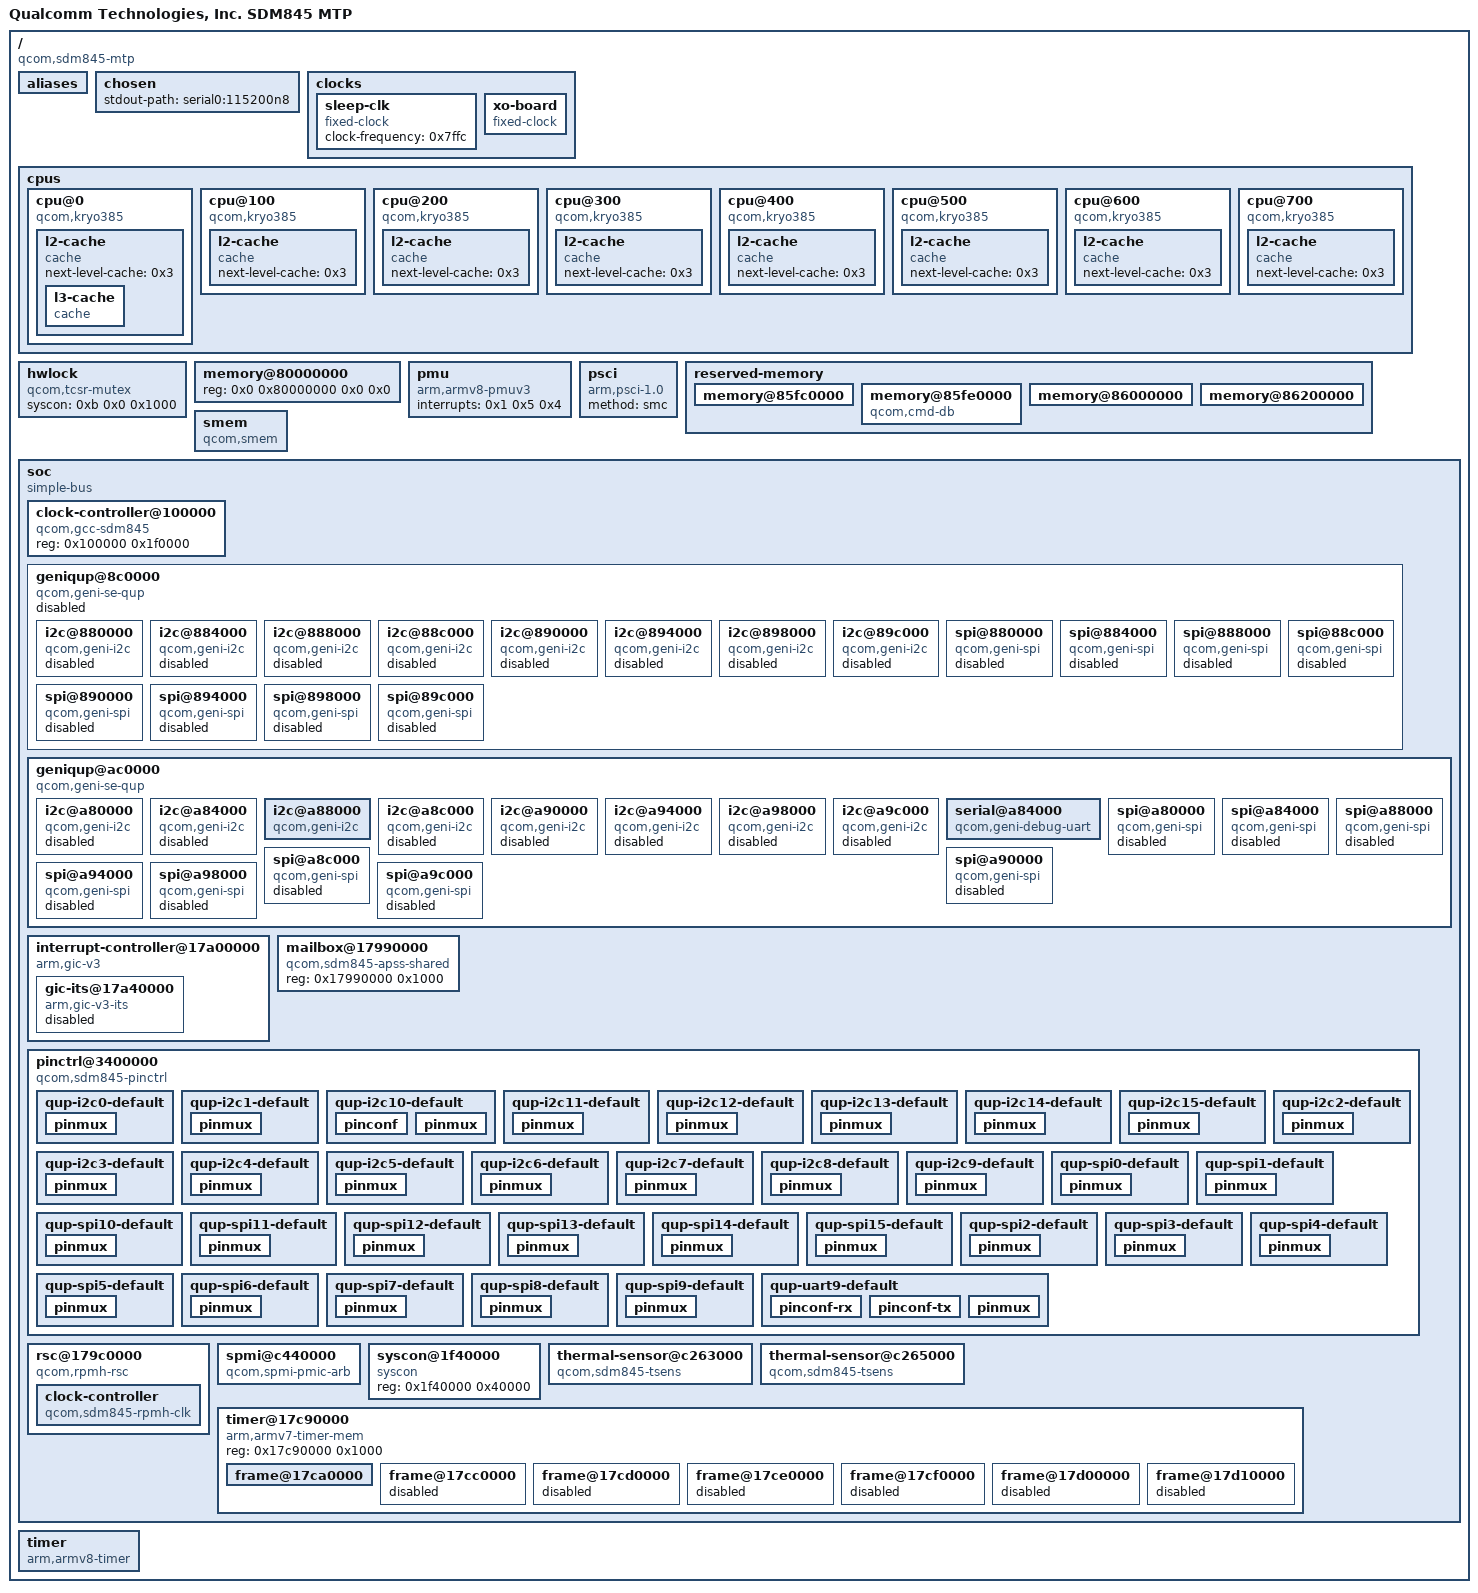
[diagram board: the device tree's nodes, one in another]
/dts-v1/;

/ {
	#address-cells = <0x2>;
	#size-cells = <0x2>;
	compatible = "qcom,sdm845-mtp";
	interrupt-parent = <0x1>;
	model = "Qualcomm Technologies, Inc. SDM845 MTP";

	__symbols__ {
		CPU0 = "/cpus/cpu@0";
		CPU1 = "/cpus/cpu@100";
		CPU2 = "/cpus/cpu@200";
		CPU3 = "/cpus/cpu@300";
		CPU4 = "/cpus/cpu@400";
		CPU5 = "/cpus/cpu@500";
		CPU6 = "/cpus/cpu@600";
		CPU7 = "/cpus/cpu@700";
		L2_0 = "/cpus/cpu@0/l2-cache";
		L2_100 = "/cpus/cpu@100/l2-cache";
		L2_200 = "/cpus/cpu@200/l2-cache";
		L2_300 = "/cpus/cpu@300/l2-cache";
		L2_400 = "/cpus/cpu@400/l2-cache";
		L2_500 = "/cpus/cpu@500/l2-cache";
		L2_600 = "/cpus/cpu@600/l2-cache";
		L2_700 = "/cpus/cpu@700/l2-cache";
		L3_0 = "/cpus/cpu@0/l2-cache/l3-cache";
		apps_rsc = "/soc/rsc@179c0000";
		apss_shared = "/soc/mailbox@17990000";
		gcc = "/soc/clock-controller@100000";
		i2c0 = "/soc/geniqup@8c0000/i2c@880000";
		i2c1 = "/soc/geniqup@8c0000/i2c@884000";
		i2c10 = "/soc/geniqup@ac0000/i2c@a88000";
		i2c11 = "/soc/geniqup@ac0000/i2c@a8c000";
		i2c12 = "/soc/geniqup@ac0000/i2c@a90000";
		i2c13 = "/soc/geniqup@ac0000/i2c@a94000";
		i2c14 = "/soc/geniqup@ac0000/i2c@a98000";
		i2c15 = "/soc/geniqup@ac0000/i2c@a9c000";
		i2c2 = "/soc/geniqup@8c0000/i2c@888000";
		i2c3 = "/soc/geniqup@8c0000/i2c@88c000";
		i2c4 = "/soc/geniqup@8c0000/i2c@890000";
		i2c5 = "/soc/geniqup@8c0000/i2c@894000";
		i2c6 = "/soc/geniqup@8c0000/i2c@898000";
		i2c7 = "/soc/geniqup@8c0000/i2c@89c000";
		i2c8 = "/soc/geniqup@ac0000/i2c@a80000";
		i2c9 = "/soc/geniqup@ac0000/i2c@a84000";
		intc = "/soc/interrupt-controller@17a00000";
		qup_i2c0_default = "/soc/pinctrl@3400000/qup-i2c0-default";
		qup_i2c10_default = "/soc/pinctrl@3400000/qup-i2c10-default";
		qup_i2c11_default = "/soc/pinctrl@3400000/qup-i2c11-default";
		qup_i2c12_default = "/soc/pinctrl@3400000/qup-i2c12-default";
		qup_i2c13_default = "/soc/pinctrl@3400000/qup-i2c13-default";
		qup_i2c14_default = "/soc/pinctrl@3400000/qup-i2c14-default";
		qup_i2c15_default = "/soc/pinctrl@3400000/qup-i2c15-default";
		qup_i2c1_default = "/soc/pinctrl@3400000/qup-i2c1-default";
		qup_i2c2_default = "/soc/pinctrl@3400000/qup-i2c2-default";
		qup_i2c3_default = "/soc/pinctrl@3400000/qup-i2c3-default";
		qup_i2c4_default = "/soc/pinctrl@3400000/qup-i2c4-default";
		qup_i2c5_default = "/soc/pinctrl@3400000/qup-i2c5-default";
		qup_i2c6_default = "/soc/pinctrl@3400000/qup-i2c6-default";
		qup_i2c7_default = "/soc/pinctrl@3400000/qup-i2c7-default";
		qup_i2c8_default = "/soc/pinctrl@3400000/qup-i2c8-default";
		qup_i2c9_default = "/soc/pinctrl@3400000/qup-i2c9-default";
		qup_spi0_default = "/soc/pinctrl@3400000/qup-spi0-default";
		qup_spi10_default = "/soc/pinctrl@3400000/qup-spi10-default";
		qup_spi11_default = "/soc/pinctrl@3400000/qup-spi11-default";
		qup_spi12_default = "/soc/pinctrl@3400000/qup-spi12-default";
		qup_spi13_default = "/soc/pinctrl@3400000/qup-spi13-default";
		qup_spi14_default = "/soc/pinctrl@3400000/qup-spi14-default";
		qup_spi15_default = "/soc/pinctrl@3400000/qup-spi15-default";
		qup_spi1_default = "/soc/pinctrl@3400000/qup-spi1-default";
		qup_spi2_default = "/soc/pinctrl@3400000/qup-spi2-default";
		qup_spi3_default = "/soc/pinctrl@3400000/qup-spi3-default";
		qup_spi4_default = "/soc/pinctrl@3400000/qup-spi4-default";
		qup_spi5_default = "/soc/pinctrl@3400000/qup-spi5-default";
		qup_spi6_default = "/soc/pinctrl@3400000/qup-spi6-default";
		qup_spi7_default = "/soc/pinctrl@3400000/qup-spi7-default";
		qup_spi8_default = "/soc/pinctrl@3400000/qup-spi8-default";
		qup_spi9_default = "/soc/pinctrl@3400000/qup-spi9-default";
		qup_uart9_default = "/soc/pinctrl@3400000/qup-uart9-default";
		qupv3_id_0 = "/soc/geniqup@8c0000";
		qupv3_id_1 = "/soc/geniqup@ac0000";
		rpmhcc = "/soc/rsc@179c0000/clock-controller";
		sleep_clk = "/clocks/sleep-clk";
		smem_mem = "/reserved-memory/memory@86000000";
		soc = "/soc";
		spi0 = "/soc/geniqup@8c0000/spi@880000";
		spi1 = "/soc/geniqup@8c0000/spi@884000";
		spi10 = "/soc/geniqup@ac0000/spi@a88000";
		spi11 = "/soc/geniqup@ac0000/spi@a8c000";
		spi12 = "/soc/geniqup@ac0000/spi@a90000";
		spi13 = "/soc/geniqup@ac0000/spi@a94000";
		spi14 = "/soc/geniqup@ac0000/spi@a98000";
		spi15 = "/soc/geniqup@ac0000/spi@a9c000";
		spi2 = "/soc/geniqup@8c0000/spi@888000";
		spi3 = "/soc/geniqup@8c0000/spi@88c000";
		spi4 = "/soc/geniqup@8c0000/spi@890000";
		spi5 = "/soc/geniqup@8c0000/spi@894000";
		spi6 = "/soc/geniqup@8c0000/spi@898000";
		spi7 = "/soc/geniqup@8c0000/spi@89c000";
		spi8 = "/soc/geniqup@ac0000/spi@a80000";
		spi9 = "/soc/geniqup@ac0000/spi@a84000";
		spmi_bus = "/soc/spmi@c440000";
		tcsr_mutex = "/hwlock";
		tcsr_mutex_regs = "/soc/syscon@1f40000";
		tlmm = "/soc/pinctrl@3400000";
		tsens0 = "/soc/thermal-sensor@c263000";
		tsens1 = "/soc/thermal-sensor@c265000";
		uart9 = "/soc/geniqup@ac0000/serial@a84000";
		xo_board = "/clocks/xo-board";
	};

	aliases {
		i2c0 = "/soc/geniqup@8c0000/i2c@880000";
		i2c1 = "/soc/geniqup@8c0000/i2c@884000";
		i2c10 = "/soc/geniqup@ac0000/i2c@a88000";
		i2c11 = "/soc/geniqup@ac0000/i2c@a8c000";
		i2c12 = "/soc/geniqup@ac0000/i2c@a90000";
		i2c13 = "/soc/geniqup@ac0000/i2c@a94000";
		i2c14 = "/soc/geniqup@ac0000/i2c@a98000";
		i2c15 = "/soc/geniqup@ac0000/i2c@a9c000";
		i2c2 = "/soc/geniqup@8c0000/i2c@888000";
		i2c3 = "/soc/geniqup@8c0000/i2c@88c000";
		i2c4 = "/soc/geniqup@8c0000/i2c@890000";
		i2c5 = "/soc/geniqup@8c0000/i2c@894000";
		i2c6 = "/soc/geniqup@8c0000/i2c@898000";
		i2c7 = "/soc/geniqup@8c0000/i2c@89c000";
		i2c8 = "/soc/geniqup@ac0000/i2c@a80000";
		i2c9 = "/soc/geniqup@ac0000/i2c@a84000";
		serial0 = "/soc/geniqup@ac0000/serial@a84000";
		spi0 = "/soc/geniqup@8c0000/spi@880000";
		spi1 = "/soc/geniqup@8c0000/spi@884000";
		spi10 = "/soc/geniqup@ac0000/spi@a88000";
		spi11 = "/soc/geniqup@ac0000/spi@a8c000";
		spi12 = "/soc/geniqup@ac0000/spi@a90000";
		spi13 = "/soc/geniqup@ac0000/spi@a94000";
		spi14 = "/soc/geniqup@ac0000/spi@a98000";
		spi15 = "/soc/geniqup@ac0000/spi@a9c000";
		spi2 = "/soc/geniqup@8c0000/spi@888000";
		spi3 = "/soc/geniqup@8c0000/spi@88c000";
		spi4 = "/soc/geniqup@8c0000/spi@890000";
		spi5 = "/soc/geniqup@8c0000/spi@894000";
		spi6 = "/soc/geniqup@8c0000/spi@898000";
		spi7 = "/soc/geniqup@8c0000/spi@89c000";
		spi8 = "/soc/geniqup@ac0000/spi@a80000";
		spi9 = "/soc/geniqup@ac0000/spi@a84000";
	};

	chosen {
		stdout-path = "serial0:115200n8";
	};

	clocks {

		sleep-clk {
			#clock-cells = <0x0>;
			clock-frequency = <0x7ffc>;
			compatible = "fixed-clock";
			linux,phandle = <0x39>;
			phandle = <0x39>;
		};

		xo-board {
			#clock-cells = <0x0>;
			clock-frequency = <0x249f000>;
			clock-output-names = "xo_board";
			compatible = "fixed-clock";
			linux,phandle = <0x38>;
			phandle = <0x38>;
		};
	};

	cpus {
		#address-cells = <0x2>;
		#size-cells = <0x0>;

		cpu@0 {
			compatible = "qcom,kryo385";
			device_type = "cpu";
			enable-method = "psci";
			linux,phandle = <0x30>;
			next-level-cache = <0x2>;
			phandle = <0x30>;
			reg = <0x0 0x0>;

			l2-cache {
				compatible = "cache";
				linux,phandle = <0x2>;
				next-level-cache = <0x3>;
				phandle = <0x2>;

				l3-cache {
					compatible = "cache";
					linux,phandle = <0x3>;
					phandle = <0x3>;
				};
			};
		};

		cpu@100 {
			compatible = "qcom,kryo385";
			device_type = "cpu";
			enable-method = "psci";
			linux,phandle = <0x31>;
			next-level-cache = <0x4>;
			phandle = <0x31>;
			reg = <0x0 0x100>;

			l2-cache {
				compatible = "cache";
				linux,phandle = <0x4>;
				next-level-cache = <0x3>;
				phandle = <0x4>;
			};
		};

		cpu@200 {
			compatible = "qcom,kryo385";
			device_type = "cpu";
			enable-method = "psci";
			linux,phandle = <0x32>;
			next-level-cache = <0x5>;
			phandle = <0x32>;
			reg = <0x0 0x200>;

			l2-cache {
				compatible = "cache";
				linux,phandle = <0x5>;
				next-level-cache = <0x3>;
				phandle = <0x5>;
			};
		};

		cpu@300 {
			compatible = "qcom,kryo385";
			device_type = "cpu";
			enable-method = "psci";
			linux,phandle = <0x33>;
			next-level-cache = <0x6>;
			phandle = <0x33>;
			reg = <0x0 0x300>;

			l2-cache {
				compatible = "cache";
				linux,phandle = <0x6>;
				next-level-cache = <0x3>;
				phandle = <0x6>;
			};
		};

		cpu@400 {
			compatible = "qcom,kryo385";
			device_type = "cpu";
			enable-method = "psci";
			linux,phandle = <0x34>;
			next-level-cache = <0x7>;
			phandle = <0x34>;
			reg = <0x0 0x400>;

			l2-cache {
				compatible = "cache";
				linux,phandle = <0x7>;
				next-level-cache = <0x3>;
				phandle = <0x7>;
			};
		};

		cpu@500 {
			compatible = "qcom,kryo385";
			device_type = "cpu";
			enable-method = "psci";
			linux,phandle = <0x35>;
			next-level-cache = <0x8>;
			phandle = <0x35>;
			reg = <0x0 0x500>;

			l2-cache {
				compatible = "cache";
				linux,phandle = <0x8>;
				next-level-cache = <0x3>;
				phandle = <0x8>;
			};
		};

		cpu@600 {
			compatible = "qcom,kryo385";
			device_type = "cpu";
			enable-method = "psci";
			linux,phandle = <0x36>;
			next-level-cache = <0x9>;
			phandle = <0x36>;
			reg = <0x0 0x600>;

			l2-cache {
				compatible = "cache";
				linux,phandle = <0x9>;
				next-level-cache = <0x3>;
				phandle = <0x9>;
			};
		};

		cpu@700 {
			compatible = "qcom,kryo385";
			device_type = "cpu";
			enable-method = "psci";
			linux,phandle = <0x37>;
			next-level-cache = <0xa>;
			phandle = <0x37>;
			reg = <0x0 0x700>;

			l2-cache {
				compatible = "cache";
				linux,phandle = <0xa>;
				next-level-cache = <0x3>;
				phandle = <0xa>;
			};
		};
	};

	hwlock {
		#hwlock-cells = <0x1>;
		compatible = "qcom,tcsr-mutex";
		linux,phandle = <0xd>;
		phandle = <0xd>;
		syscon = <0xb 0x0 0x1000>;
	};

	memory@80000000 {
		device_type = "memory";
		reg = <0x0 0x80000000 0x0 0x0>;
	};

	pmu {
		compatible = "arm,armv8-pmuv3";
		interrupts = <0x1 0x5 0x4>;
	};

	psci {
		compatible = "arm,psci-1.0";
		method = "smc";
	};

	reserved-memory {
		#address-cells = <0x2>;
		#size-cells = <0x2>;
		ranges;

		memory@85fc0000 {
			no-map;
			reg = <0x0 0x85fc0000 0x0 0x20000>;
		};

		memory@85fe0000 {
			compatible = "qcom,cmd-db";
			no-map;
			reg = <0x0 0x85fe0000 0x0 0x20000>;
		};

		memory@86000000 {
			linux,phandle = <0xc>;
			no-map;
			phandle = <0xc>;
			reg = <0x0 0x86000000 0x0 0x200000>;
		};

		memory@86200000 {
			no-map;
			reg = <0x0 0x86200000 0x0 0x2d00000>;
		};
	};

	smem {
		compatible = "qcom,smem";
		hwlocks = <0xd 0x3>;
		memory-region = <0xc>;
	};

	soc {
		#address-cells = <0x1>;
		#size-cells = <0x1>;
		compatible = "simple-bus";
		linux,phandle = <0x3a>;
		phandle = <0x3a>;
		ranges = <0x0 0x0 0x0 0xffffffff>;

		clock-controller@100000 {
			#clock-cells = <0x1>;
			#power-domain-cells = <0x1>;
			#reset-cells = <0x1>;
			compatible = "qcom,gcc-sdm845";
			linux,phandle = <0xe>;
			phandle = <0xe>;
			reg = <0x100000 0x1f0000>;
		};

		geniqup@8c0000 {
			#address-cells = <0x1>;
			#size-cells = <0x1>;
			clock-names = "m-ahb", "s-ahb";
			clocks = <0xe 0x64 0xe 0x65>;
			compatible = "qcom,geni-se-qup";
			linux,phandle = <0x3b>;
			phandle = <0x3b>;
			ranges;
			reg = <0x8c0000 0x6000>;
			status = "disabled";

			i2c@880000 {
				#address-cells = <0x1>;
				#size-cells = <0x0>;
				clock-names = "se";
				clocks = <0xe 0x44>;
				compatible = "qcom,geni-i2c";
				interrupts = <0x0 0x259 0x4>;
				linux,phandle = <0x3c>;
				phandle = <0x3c>;
				pinctrl-0 = <0xf>;
				pinctrl-names = "default";
				reg = <0x880000 0x4000>;
				status = "disabled";
			};

			i2c@884000 {
				#address-cells = <0x1>;
				#size-cells = <0x0>;
				clock-names = "se";
				clocks = <0xe 0x46>;
				compatible = "qcom,geni-i2c";
				interrupts = <0x0 0x25a 0x4>;
				linux,phandle = <0x3e>;
				phandle = <0x3e>;
				pinctrl-0 = <0x11>;
				pinctrl-names = "default";
				reg = <0x884000 0x4000>;
				status = "disabled";
			};

			i2c@888000 {
				#address-cells = <0x1>;
				#size-cells = <0x0>;
				clock-names = "se";
				clocks = <0xe 0x48>;
				compatible = "qcom,geni-i2c";
				interrupts = <0x0 0x25b 0x4>;
				linux,phandle = <0x40>;
				phandle = <0x40>;
				pinctrl-0 = <0x13>;
				pinctrl-names = "default";
				reg = <0x888000 0x4000>;
				status = "disabled";
			};

			i2c@88c000 {
				#address-cells = <0x1>;
				#size-cells = <0x0>;
				clock-names = "se";
				clocks = <0xe 0x4a>;
				compatible = "qcom,geni-i2c";
				interrupts = <0x0 0x25c 0x4>;
				linux,phandle = <0x42>;
				phandle = <0x42>;
				pinctrl-0 = <0x15>;
				pinctrl-names = "default";
				reg = <0x88c000 0x4000>;
				status = "disabled";
			};

			i2c@890000 {
				#address-cells = <0x1>;
				#size-cells = <0x0>;
				clock-names = "se";
				clocks = <0xe 0x4c>;
				compatible = "qcom,geni-i2c";
				interrupts = <0x0 0x25d 0x4>;
				linux,phandle = <0x44>;
				phandle = <0x44>;
				pinctrl-0 = <0x17>;
				pinctrl-names = "default";
				reg = <0x890000 0x4000>;
				status = "disabled";
			};

			i2c@894000 {
				#address-cells = <0x1>;
				#size-cells = <0x0>;
				clock-names = "se";
				clocks = <0xe 0x4e>;
				compatible = "qcom,geni-i2c";
				interrupts = <0x0 0x25e 0x4>;
				linux,phandle = <0x46>;
				phandle = <0x46>;
				pinctrl-0 = <0x19>;
				pinctrl-names = "default";
				reg = <0x894000 0x4000>;
				status = "disabled";
			};

			i2c@898000 {
				#address-cells = <0x1>;
				#size-cells = <0x0>;
				clock-names = "se";
				clocks = <0xe 0x50>;
				compatible = "qcom,geni-i2c";
				interrupts = <0x0 0x25f 0x4>;
				linux,phandle = <0x48>;
				phandle = <0x48>;
				pinctrl-0 = <0x1b>;
				pinctrl-names = "default";
				reg = <0x898000 0x4000>;
				status = "disabled";
			};

			i2c@89c000 {
				#address-cells = <0x1>;
				#size-cells = <0x0>;
				clock-names = "se";
				clocks = <0xe 0x52>;
				compatible = "qcom,geni-i2c";
				interrupts = <0x0 0x260 0x4>;
				linux,phandle = <0x4a>;
				phandle = <0x4a>;
				pinctrl-0 = <0x1d>;
				pinctrl-names = "default";
				reg = <0x89c000 0x4000>;
				status = "disabled";
			};

			spi@880000 {
				#address-cells = <0x1>;
				#size-cells = <0x0>;
				clock-names = "se";
				clocks = <0xe 0x44>;
				compatible = "qcom,geni-spi";
				interrupts = <0x0 0x259 0x4>;
				linux,phandle = <0x3d>;
				phandle = <0x3d>;
				pinctrl-0 = <0x10>;
				pinctrl-names = "default";
				reg = <0x880000 0x4000>;
				status = "disabled";
			};

			spi@884000 {
				#address-cells = <0x1>;
				#size-cells = <0x0>;
				clock-names = "se";
				clocks = <0xe 0x46>;
				compatible = "qcom,geni-spi";
				interrupts = <0x0 0x25a 0x4>;
				linux,phandle = <0x3f>;
				phandle = <0x3f>;
				pinctrl-0 = <0x12>;
				pinctrl-names = "default";
				reg = <0x884000 0x4000>;
				status = "disabled";
			};

			spi@888000 {
				#address-cells = <0x1>;
				#size-cells = <0x0>;
				clock-names = "se";
				clocks = <0xe 0x48>;
				compatible = "qcom,geni-spi";
				interrupts = <0x0 0x25b 0x4>;
				linux,phandle = <0x41>;
				phandle = <0x41>;
				pinctrl-0 = <0x14>;
				pinctrl-names = "default";
				reg = <0x888000 0x4000>;
				status = "disabled";
			};

			spi@88c000 {
				#address-cells = <0x1>;
				#size-cells = <0x0>;
				clock-names = "se";
				clocks = <0xe 0x4a>;
				compatible = "qcom,geni-spi";
				interrupts = <0x0 0x25c 0x4>;
				linux,phandle = <0x43>;
				phandle = <0x43>;
				pinctrl-0 = <0x16>;
				pinctrl-names = "default";
				reg = <0x88c000 0x4000>;
				status = "disabled";
			};

			spi@890000 {
				#address-cells = <0x1>;
				#size-cells = <0x0>;
				clock-names = "se";
				clocks = <0xe 0x4c>;
				compatible = "qcom,geni-spi";
				interrupts = <0x0 0x25d 0x4>;
				linux,phandle = <0x45>;
				phandle = <0x45>;
				pinctrl-0 = <0x18>;
				pinctrl-names = "default";
				reg = <0x890000 0x4000>;
				status = "disabled";
			};

			spi@894000 {
				#address-cells = <0x1>;
				#size-cells = <0x0>;
				clock-names = "se";
				clocks = <0xe 0x4e>;
				compatible = "qcom,geni-spi";
				interrupts = <0x0 0x25e 0x4>;
				linux,phandle = <0x47>;
				phandle = <0x47>;
				pinctrl-0 = <0x1a>;
				pinctrl-names = "default";
				reg = <0x894000 0x4000>;
				status = "disabled";
			};

			spi@898000 {
				#address-cells = <0x1>;
				#size-cells = <0x0>;
				clock-names = "se";
				clocks = <0xe 0x50>;
				compatible = "qcom,geni-spi";
				interrupts = <0x0 0x25f 0x4>;
				linux,phandle = <0x49>;
				phandle = <0x49>;
				pinctrl-0 = <0x1c>;
				pinctrl-names = "default";
				reg = <0x898000 0x4000>;
				status = "disabled";
			};

			spi@89c000 {
				#address-cells = <0x1>;
				#size-cells = <0x0>;
				clock-names = "se";
				clocks = <0xe 0x52>;
				compatible = "qcom,geni-spi";
				interrupts = <0x0 0x260 0x4>;
				linux,phandle = <0x4b>;
				phandle = <0x4b>;
				pinctrl-0 = <0x1e>;
				pinctrl-names = "default";
				reg = <0x89c000 0x4000>;
				status = "disabled";
			};
		};

		geniqup@ac0000 {
			#address-cells = <0x1>;
			#size-cells = <0x1>;
			clock-names = "m-ahb", "s-ahb";
			clocks = <0xe 0x66 0xe 0x67>;
			compatible = "qcom,geni-se-qup";
			linux,phandle = <0x4c>;
			phandle = <0x4c>;
			ranges;
			reg = <0xac0000 0x6000>;
			status = "okay";

			i2c@a80000 {
				#address-cells = <0x1>;
				#size-cells = <0x0>;
				clock-names = "se";
				clocks = <0xe 0x54>;
				compatible = "qcom,geni-i2c";
				interrupts = <0x0 0x161 0x4>;
				linux,phandle = <0x4d>;
				phandle = <0x4d>;
				pinctrl-0 = <0x1f>;
				pinctrl-names = "default";
				reg = <0xa80000 0x4000>;
				status = "disabled";
			};

			i2c@a84000 {
				#address-cells = <0x1>;
				#size-cells = <0x0>;
				clock-names = "se";
				clocks = <0xe 0x56>;
				compatible = "qcom,geni-i2c";
				interrupts = <0x0 0x162 0x4>;
				linux,phandle = <0x4f>;
				phandle = <0x4f>;
				pinctrl-0 = <0x21>;
				pinctrl-names = "default";
				reg = <0xa84000 0x4000>;
				status = "disabled";
			};

			i2c@a88000 {
				#address-cells = <0x1>;
				#size-cells = <0x0>;
				clock-frequency = <0x61a80>;
				clock-names = "se";
				clocks = <0xe 0x58>;
				compatible = "qcom,geni-i2c";
				interrupts = <0x0 0x163 0x4>;
				linux,phandle = <0x52>;
				phandle = <0x52>;
				pinctrl-0 = <0x24>;
				pinctrl-names = "default";
				reg = <0xa88000 0x4000>;
				status = "okay";
			};

			i2c@a8c000 {
				#address-cells = <0x1>;
				#size-cells = <0x0>;
				clock-names = "se";
				clocks = <0xe 0x5a>;
				compatible = "qcom,geni-i2c";
				interrupts = <0x0 0x164 0x4>;
				linux,phandle = <0x54>;
				phandle = <0x54>;
				pinctrl-0 = <0x26>;
				pinctrl-names = "default";
				reg = <0xa8c000 0x4000>;
				status = "disabled";
			};

			i2c@a90000 {
				#address-cells = <0x1>;
				#size-cells = <0x0>;
				clock-names = "se";
				clocks = <0xe 0x5c>;
				compatible = "qcom,geni-i2c";
				interrupts = <0x0 0x165 0x4>;
				linux,phandle = <0x56>;
				phandle = <0x56>;
				pinctrl-0 = <0x28>;
				pinctrl-names = "default";
				reg = <0xa90000 0x4000>;
				status = "disabled";
			};

			i2c@a94000 {
				#address-cells = <0x1>;
				#size-cells = <0x0>;
				clock-names = "se";
				clocks = <0xe 0x5e>;
				compatible = "qcom,geni-i2c";
				interrupts = <0x0 0x166 0x4>;
				linux,phandle = <0x58>;
				phandle = <0x58>;
				pinctrl-0 = <0x2a>;
				pinctrl-names = "default";
				reg = <0xa94000 0x4000>;
				status = "disabled";
			};

			i2c@a98000 {
				#address-cells = <0x1>;
				#size-cells = <0x0>;
				clock-names = "se";
				clocks = <0xe 0x60>;
				compatible = "qcom,geni-i2c";
				interrupts = <0x0 0x167 0x4>;
				linux,phandle = <0x5a>;
				phandle = <0x5a>;
				pinctrl-0 = <0x2c>;
				pinctrl-names = "default";
				reg = <0xa98000 0x4000>;
				status = "disabled";
			};

			i2c@a9c000 {
				#address-cells = <0x1>;
				#size-cells = <0x0>;
				clock-names = "se";
				clocks = <0xe 0x62>;
				compatible = "qcom,geni-i2c";
				interrupts = <0x0 0x168 0x4>;
				linux,phandle = <0x5c>;
				phandle = <0x5c>;
				pinctrl-0 = <0x2e>;
				pinctrl-names = "default";
				reg = <0xa9c000 0x4000>;
				status = "disabled";
			};

			serial@a84000 {
				clock-names = "se";
				clocks = <0xe 0x56>;
				compatible = "qcom,geni-debug-uart";
				interrupts = <0x0 0x162 0x4>;
				linux,phandle = <0x51>;
				phandle = <0x51>;
				pinctrl-0 = <0x23>;
				pinctrl-names = "default";
				reg = <0xa84000 0x4000>;
				status = "okay";
			};

			spi@a80000 {
				#address-cells = <0x1>;
				#size-cells = <0x0>;
				clock-names = "se";
				clocks = <0xe 0x54>;
				compatible = "qcom,geni-spi";
				interrupts = <0x0 0x161 0x4>;
				linux,phandle = <0x4e>;
				phandle = <0x4e>;
				pinctrl-0 = <0x20>;
				pinctrl-names = "default";
				reg = <0xa80000 0x4000>;
				status = "disabled";
			};

			spi@a84000 {
				#address-cells = <0x1>;
				#size-cells = <0x0>;
				clock-names = "se";
				clocks = <0xe 0x56>;
				compatible = "qcom,geni-spi";
				interrupts = <0x0 0x162 0x4>;
				linux,phandle = <0x50>;
				phandle = <0x50>;
				pinctrl-0 = <0x22>;
				pinctrl-names = "default";
				reg = <0xa84000 0x4000>;
				status = "disabled";
			};

			spi@a88000 {
				#address-cells = <0x1>;
				#size-cells = <0x0>;
				clock-names = "se";
				clocks = <0xe 0x58>;
				compatible = "qcom,geni-spi";
				interrupts = <0x0 0x163 0x4>;
				linux,phandle = <0x53>;
				phandle = <0x53>;
				pinctrl-0 = <0x25>;
				pinctrl-names = "default";
				reg = <0xa88000 0x4000>;
				status = "disabled";
			};

			spi@a8c000 {
				#address-cells = <0x1>;
				#size-cells = <0x0>;
				clock-names = "se";
				clocks = <0xe 0x5a>;
				compatible = "qcom,geni-spi";
				interrupts = <0x0 0x164 0x4>;
				linux,phandle = <0x55>;
				phandle = <0x55>;
				pinctrl-0 = <0x27>;
				pinctrl-names = "default";
				reg = <0xa8c000 0x4000>;
				status = "disabled";
			};

			spi@a90000 {
				#address-cells = <0x1>;
				#size-cells = <0x0>;
				clock-names = "se";
				clocks = <0xe 0x5c>;
				compatible = "qcom,geni-spi";
				interrupts = <0x0 0x165 0x4>;
				linux,phandle = <0x57>;
				phandle = <0x57>;
				pinctrl-0 = <0x29>;
				pinctrl-names = "default";
				reg = <0xa90000 0x4000>;
				status = "disabled";
			};

			spi@a94000 {
				#address-cells = <0x1>;
				#size-cells = <0x0>;
				clock-names = "se";
				clocks = <0xe 0x5e>;
				compatible = "qcom,geni-spi";
				interrupts = <0x0 0x166 0x4>;
				linux,phandle = <0x59>;
				phandle = <0x59>;
				pinctrl-0 = <0x2b>;
				pinctrl-names = "default";
				reg = <0xa94000 0x4000>;
				status = "disabled";
			};

			spi@a98000 {
				#address-cells = <0x1>;
				#size-cells = <0x0>;
				clock-names = "se";
				clocks = <0xe 0x60>;
				compatible = "qcom,geni-spi";
				interrupts = <0x0 0x167 0x4>;
				linux,phandle = <0x5b>;
				phandle = <0x5b>;
				pinctrl-0 = <0x2d>;
				pinctrl-names = "default";
				reg = <0xa98000 0x4000>;
				status = "disabled";
			};

			spi@a9c000 {
				#address-cells = <0x1>;
				#size-cells = <0x0>;
				clock-names = "se";
				clocks = <0xe 0x62>;
				compatible = "qcom,geni-spi";
				interrupts = <0x0 0x168 0x4>;
				linux,phandle = <0x5d>;
				phandle = <0x5d>;
				pinctrl-0 = <0x2f>;
				pinctrl-names = "default";
				reg = <0xa9c000 0x4000>;
				status = "disabled";
			};
		};

		interrupt-controller@17a00000 {
			#address-cells = <0x1>;
			#interrupt-cells = <0x3>;
			#size-cells = <0x1>;
			compatible = "arm,gic-v3";
			interrupt-controller;
			interrupts = <0x1 0x9 0x4>;
			linux,phandle = <0x1>;
			phandle = <0x1>;
			ranges;
			reg = <0x17a00000 0x10000 0x17a60000 0x100000>;

			gic-its@17a40000 {
				#msi-cells = <0x1>;
				compatible = "arm,gic-v3-its";
				msi-controller;
				reg = <0x17a40000 0x20000>;
				status = "disabled";
			};
		};

		mailbox@17990000 {
			#mbox-cells = <0x1>;
			compatible = "qcom,sdm845-apss-shared";
			linux,phandle = <0x62>;
			phandle = <0x62>;
			reg = <0x17990000 0x1000>;
		};

		pinctrl@3400000 {
			#gpio-cells = <0x2>;
			#interrupt-cells = <0x2>;
			compatible = "qcom,sdm845-pinctrl";
			gpio-controller;
			gpio-reserved-ranges = <0x0 0x4 0x51 0x4>;
			interrupt-controller;
			interrupts = <0x0 0xd0 0x4>;
			linux,phandle = <0x5e>;
			phandle = <0x5e>;
			reg = <0x3400000 0xc00000>;

			qup-i2c0-default {
				linux,phandle = <0xf>;
				phandle = <0xf>;

				pinmux {
					function = "qup0";
					pins = "gpio0", "gpio1";
				};
			};

			qup-i2c1-default {
				linux,phandle = <0x11>;
				phandle = <0x11>;

				pinmux {
					function = "qup1";
					pins = "gpio17", "gpio18";
				};
			};

			qup-i2c10-default {
				linux,phandle = <0x24>;
				phandle = <0x24>;

				pinconf {
					bias-disable;
					drive-strength = <0x2>;
					pins = "gpio55", "gpio56";
				};

				pinmux {
					function = "qup10";
					pins = "gpio55", "gpio56";
				};
			};

			qup-i2c11-default {
				linux,phandle = <0x26>;
				phandle = <0x26>;

				pinmux {
					function = "qup11";
					pins = "gpio31", "gpio32";
				};
			};

			qup-i2c12-default {
				linux,phandle = <0x28>;
				phandle = <0x28>;

				pinmux {
					function = "qup12";
					pins = "gpio49", "gpio50";
				};
			};

			qup-i2c13-default {
				linux,phandle = <0x2a>;
				phandle = <0x2a>;

				pinmux {
					function = "qup13";
					pins = "gpio105", "gpio106";
				};
			};

			qup-i2c14-default {
				linux,phandle = <0x2c>;
				phandle = <0x2c>;

				pinmux {
					function = "qup14";
					pins = "gpio33", "gpio34";
				};
			};

			qup-i2c15-default {
				linux,phandle = <0x2e>;
				phandle = <0x2e>;

				pinmux {
					function = "qup15";
					pins = "gpio81", "gpio82";
				};
			};

			qup-i2c2-default {
				linux,phandle = <0x13>;
				phandle = <0x13>;

				pinmux {
					function = "qup2";
					pins = "gpio27", "gpio28";
				};
			};

			qup-i2c3-default {
				linux,phandle = <0x15>;
				phandle = <0x15>;

				pinmux {
					function = "qup3";
					pins = "gpio41", "gpio42";
				};
			};

			qup-i2c4-default {
				linux,phandle = <0x17>;
				phandle = <0x17>;

				pinmux {
					function = "qup4";
					pins = "gpio89", "gpio90";
				};
			};

			qup-i2c5-default {
				linux,phandle = <0x19>;
				phandle = <0x19>;

				pinmux {
					function = "qup5";
					pins = "gpio85", "gpio86";
				};
			};

			qup-i2c6-default {
				linux,phandle = <0x1b>;
				phandle = <0x1b>;

				pinmux {
					function = "qup6";
					pins = "gpio45", "gpio46";
				};
			};

			qup-i2c7-default {
				linux,phandle = <0x1d>;
				phandle = <0x1d>;

				pinmux {
					function = "qup7";
					pins = "gpio93", "gpio94";
				};
			};

			qup-i2c8-default {
				linux,phandle = <0x1f>;
				phandle = <0x1f>;

				pinmux {
					function = "qup8";
					pins = "gpio65", "gpio66";
				};
			};

			qup-i2c9-default {
				linux,phandle = <0x21>;
				phandle = <0x21>;

				pinmux {
					function = "qup9";
					pins = "gpio6", "gpio7";
				};
			};

			qup-spi0-default {
				linux,phandle = <0x10>;
				phandle = <0x10>;

				pinmux {
					function = "qup0";
					pins = "gpio0", "gpio1", "gpio2", "gpio3";
				};
			};

			qup-spi1-default {
				linux,phandle = <0x12>;
				phandle = <0x12>;

				pinmux {
					function = "qup1";
					pins = "gpio17", "gpio18", "gpio19", "gpio20";
				};
			};

			qup-spi10-default {
				linux,phandle = <0x25>;
				phandle = <0x25>;

				pinmux {
					function = "qup10";
					pins = "gpio55", "gpio56", "gpio53", "gpio54";
				};
			};

			qup-spi11-default {
				linux,phandle = <0x27>;
				phandle = <0x27>;

				pinmux {
					function = "qup11";
					pins = "gpio31", "gpio32", "gpio33", "gpio34";
				};
			};

			qup-spi12-default {
				linux,phandle = <0x29>;
				phandle = <0x29>;

				pinmux {
					function = "qup12";
					pins = "gpio49", "gpio50", "gpio51", "gpio52";
				};
			};

			qup-spi13-default {
				linux,phandle = <0x2b>;
				phandle = <0x2b>;

				pinmux {
					function = "qup13";
					pins = "gpio105", "gpio106", "gpio107", "gpio108";
				};
			};

			qup-spi14-default {
				linux,phandle = <0x2d>;
				phandle = <0x2d>;

				pinmux {
					function = "qup14";
					pins = "gpio33", "gpio34", "gpio31", "gpio32";
				};
			};

			qup-spi15-default {
				linux,phandle = <0x2f>;
				phandle = <0x2f>;

				pinmux {
					function = "qup15";
					pins = "gpio81", "gpio82", "gpio83", "gpio84";
				};
			};

			qup-spi2-default {
				linux,phandle = <0x14>;
				phandle = <0x14>;

				pinmux {
					function = "qup2";
					pins = "gpio27", "gpio28", "gpio29", "gpio30";
				};
			};

			qup-spi3-default {
				linux,phandle = <0x16>;
				phandle = <0x16>;

				pinmux {
					function = "qup3";
					pins = "gpio41", "gpio42", "gpio43", "gpio44";
				};
			};

			qup-spi4-default {
				linux,phandle = <0x18>;
				phandle = <0x18>;

				pinmux {
					function = "qup4";
					pins = "gpio89", "gpio90", "gpio91", "gpio92";
				};
			};

			qup-spi5-default {
				linux,phandle = <0x1a>;
				phandle = <0x1a>;

				pinmux {
					function = "qup5";
					pins = "gpio85", "gpio86", "gpio87", "gpio88";
				};
			};

			qup-spi6-default {
				linux,phandle = <0x1c>;
				phandle = <0x1c>;

				pinmux {
					function = "qup6";
					pins = "gpio45", "gpio46", "gpio47", "gpio48";
				};
			};

			qup-spi7-default {
				linux,phandle = <0x1e>;
				phandle = <0x1e>;

				pinmux {
					function = "qup7";
					pins = "gpio93", "gpio94", "gpio95", "gpio96";
				};
			};

			qup-spi8-default {
				linux,phandle = <0x20>;
				phandle = <0x20>;

				pinmux {
					function = "qup8";
					pins = "gpio65", "gpio66", "gpio67", "gpio68";
				};
			};

			qup-spi9-default {
				linux,phandle = <0x22>;
				phandle = <0x22>;

				pinmux {
					function = "qup9";
					pins = "gpio6", "gpio7", "gpio4", "gpio5";
				};
			};

			qup-uart9-default {
				linux,phandle = <0x23>;
				phandle = <0x23>;

				pinconf-rx {
					bias-pull-up;
					drive-strength = <0x2>;
					pins = "gpio5";
				};

				pinconf-tx {
					bias-disable;
					drive-strength = <0x2>;
					pins = "gpio4";
				};

				pinmux {
					function = "qup9";
					pins = "gpio4", "gpio5";
				};
			};
		};

		rsc@179c0000 {
			compatible = "qcom,rpmh-rsc";
			interrupts = <0x0 0x3 0x4 0x0 0x4 0x4 0x0 0x5 0x4>;
			label = "apps_rsc";
			linux,phandle = <0x63>;
			phandle = <0x63>;
			qcom,drv-id = <0x2>;
			qcom,tcs-config = <0x2 0x2 0x0 0x3 0x1 0x3 0x3 0x1>;
			qcom,tcs-offset = <0xd00>;
			reg = <0x179c0000 0x10000 0x179d0000 0x10000 0x179e0000 0x10000>;
			reg-names = "drv-0", "drv-1", "drv-2";

			clock-controller {
				#clock-cells = <0x1>;
				compatible = "qcom,sdm845-rpmh-clk";
				linux,phandle = <0x64>;
				phandle = <0x64>;
			};
		};

		spmi@c440000 {
			#address-cells = <0x2>;
			#interrupt-cells = <0x4>;
			#size-cells = <0x0>;
			cell-index = <0x0>;
			compatible = "qcom,spmi-pmic-arb";
			interrupt-controller;
			interrupt-names = "periph_irq";
			interrupts = <0x0 0x1e1 0x4>;
			linux,phandle = <0x61>;
			phandle = <0x61>;
			qcom,channel = <0x0>;
			qcom,ee = <0x0>;
			reg = <0xc440000 0x1100 0xc600000 0x2000000 0xe600000 0x100000 0xe700000 0xa0000 0xc40a000 0x26000>;
			reg-names = "core", "chnls", "obsrvr", "intr", "cnfg";
		};

		syscon@1f40000 {
			compatible = "syscon";
			linux,phandle = <0xb>;
			phandle = <0xb>;
			reg = <0x1f40000 0x40000>;
		};

		thermal-sensor@c263000 {
			#qcom,sensors = <0xd>;
			#thermal-sensor-cells = <0x1>;
			compatible = "qcom,sdm845-tsens", "qcom,tsens-v2";
			linux,phandle = <0x5f>;
			phandle = <0x5f>;
			reg = <0xc263000 0x1ff 0xc222000 0x1ff>;
		};

		thermal-sensor@c265000 {
			#qcom,sensors = <0x8>;
			#thermal-sensor-cells = <0x1>;
			compatible = "qcom,sdm845-tsens", "qcom,tsens-v2";
			linux,phandle = <0x60>;
			phandle = <0x60>;
			reg = <0xc265000 0x1ff 0xc223000 0x1ff>;
		};

		timer@17c90000 {
			#address-cells = <0x1>;
			#size-cells = <0x1>;
			compatible = "arm,armv7-timer-mem";
			ranges;
			reg = <0x17c90000 0x1000>;

			frame@17ca0000 {
				frame-number = <0x0>;
				interrupts = <0x0 0x7 0x4 0x0 0x6 0x4>;
				reg = <0x17ca0000 0x1000 0x17cb0000 0x1000>;
			};

			frame@17cc0000 {
				frame-number = <0x1>;
				interrupts = <0x0 0x8 0x4>;
				reg = <0x17cc0000 0x1000>;
				status = "disabled";
			};

			frame@17cd0000 {
				frame-number = <0x2>;
				interrupts = <0x0 0x9 0x4>;
				reg = <0x17cd0000 0x1000>;
				status = "disabled";
			};

			frame@17ce0000 {
				frame-number = <0x3>;
				interrupts = <0x0 0xa 0x4>;
				reg = <0x17ce0000 0x1000>;
				status = "disabled";
			};

			frame@17cf0000 {
				frame-number = <0x4>;
				interrupts = <0x0 0xb 0x4>;
				reg = <0x17cf0000 0x1000>;
				status = "disabled";
			};

			frame@17d00000 {
				frame-number = <0x5>;
				interrupts = <0x0 0xc 0x4>;
				reg = <0x17d00000 0x1000>;
				status = "disabled";
			};

			frame@17d10000 {
				frame-number = <0x6>;
				interrupts = <0x0 0xd 0x4>;
				reg = <0x17d10000 0x1000>;
				status = "disabled";
			};
		};
	};

	timer {
		compatible = "arm,armv8-timer";
		interrupts = <0x1 0x1 0x8 0x1 0x2 0x8 0x1 0x3 0x8 0x1 0x0 0x8>;
	};
};
